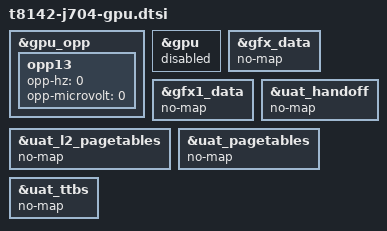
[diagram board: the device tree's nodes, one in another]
// SPDX-License-Identifier: GPL-2.0+ OR MIT

&gpu_opp {
	/* J704 has fourteen source performance states, including the off state. */
	opp13 { opp-hz = /bits/ 64 <0>; opp-microvolt = <0>; };
};

&gpu {
	/* Enabled only after the loader publishes a supported firmware profile. */
	status = "disabled";
};

/* Firmware-owned regions must never be allocated or mapped by the linear map. */
&gfx_data { no-map; };
&gfx1_data { no-map; };
&uat_handoff { no-map; };
&uat_l2_pagetables { no-map; };
&uat_pagetables { no-map; };
&uat_ttbs { no-map; };
